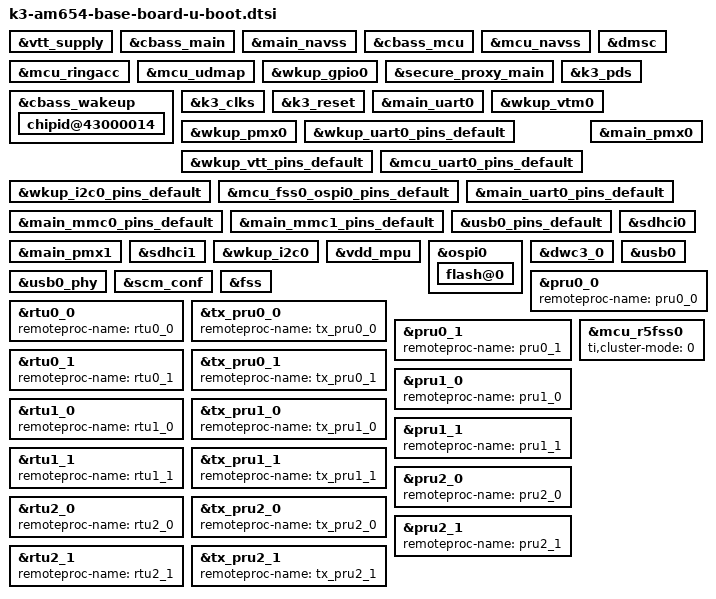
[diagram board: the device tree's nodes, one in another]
// SPDX-License-Identifier: GPL-2.0
/*
 * Copyright (C) 2018-2021 Texas Instruments Incorporated - https://www.ti.com/
 */

#include "k3-am65x-binman.dtsi"

&vtt_supply {
	bootph-pre-ram;
};

&cbass_main {
	bootph-pre-ram;
};

&main_navss {
	bootph-pre-ram;
};

&cbass_mcu {
	bootph-pre-ram;
};

&mcu_navss {
	bootph-pre-ram;
};

&mcu_ringacc {
	bootph-pre-ram;
};

&mcu_udmap {
	bootph-pre-ram;
};

&wkup_gpio0 {
	bootph-pre-ram;
};

&secure_proxy_main {
	bootph-pre-ram;
};

&cbass_wakeup {
	bootph-pre-ram;

	chipid@43000014 {
		bootph-pre-ram;
	};
};

&dmsc {
	bootph-pre-ram;
};

&k3_pds {
	bootph-pre-ram;
};

&k3_clks {
	bootph-pre-ram;
};

&k3_reset {
	bootph-pre-ram;
};

&main_uart0 {
	bootph-pre-ram;
};

&wkup_vtm0 {
	bootph-pre-ram;
};

&wkup_pmx0 {
	bootph-pre-ram;
};

&wkup_uart0_pins_default {
	bootph-pre-ram;
};

&wkup_vtt_pins_default {
	bootph-pre-ram;
};

&mcu_uart0_pins_default {
	bootph-pre-ram;
};

&wkup_i2c0_pins_default {
	bootph-pre-ram;
};

&mcu_fss0_ospi0_pins_default {
	bootph-pre-ram;
};

&main_pmx0 {
	bootph-pre-ram;
};

&main_uart0_pins_default {
	bootph-pre-ram;
};

&main_mmc0_pins_default {
	bootph-pre-ram;
};

&main_mmc1_pins_default {
	bootph-pre-ram;
};

&usb0_pins_default {
	bootph-pre-ram;
};

&main_pmx1 {
	bootph-pre-ram;
};

&sdhci0 {
	bootph-pre-ram;
};

&sdhci1 {
	bootph-pre-ram;
};

&wkup_i2c0 {
	bootph-pre-ram;
};

&vdd_mpu {
	bootph-pre-ram;
};

&ospi0 {
	bootph-pre-ram;

	flash@0 {
		bootph-pre-ram;
	};
};

&dwc3_0 {
	bootph-pre-ram;
};

&usb0_phy {
	bootph-pre-ram;
};

&usb0 {
	bootph-pre-ram;
};

&scm_conf {
	bootph-pre-ram;
};

&fss {
	bootph-pre-ram;
};

&pru0_0 {
	remoteproc-name = "pru0_0";
};

&rtu0_0 {
	remoteproc-name = "rtu0_0";
};

&tx_pru0_0 {
	remoteproc-name = "tx_pru0_0";
};

&pru0_1 {
	remoteproc-name = "pru0_1";
};

&rtu0_1 {
	remoteproc-name = "rtu0_1";
};

&tx_pru0_1 {
	remoteproc-name = "tx_pru0_1";
};

&pru1_0 {
	remoteproc-name = "pru1_0";
};

&rtu1_0 {
	remoteproc-name = "rtu1_0";
};

&tx_pru1_0 {
	remoteproc-name = "tx_pru1_0";
};

&pru1_1 {
	remoteproc-name = "pru1_1";
};

&rtu1_1 {
	remoteproc-name = "rtu1_1";
};

&tx_pru1_1 {
	remoteproc-name = "tx_pru1_1";
};

&pru2_0 {
	remoteproc-name = "pru2_0";
};

&rtu2_0 {
	remoteproc-name = "rtu2_0";
};

&tx_pru2_0 {
	remoteproc-name = "tx_pru2_0";
};

&pru2_1 {
	remoteproc-name = "pru2_1";
};

&rtu2_1 {
	remoteproc-name = "rtu2_1";
};

&tx_pru2_1 {
	remoteproc-name = "tx_pru2_1";
};

&mcu_r5fss0 {
	ti,cluster-mode = <0>;
};
